# SF32LB56x register map
File version: 1.0
CPU: CM33 r0p1, little endian, MPU, FPU, 3 interrupt priority bits
Registers are 32-bit, read-write, reset 0x0 unless marked. A register's access mark holds for its fields unless they carry their own. Offsets are from the block's base; [hi:lo] are bit positions; {n}, {i} and the like mark numbered series; 'fields as' and 'values as' point back to an identical list.

## HPSYS_CFG
Base 0x4000B000
0x00 BMR — Boot Mode Register
  [0] BOOT_MODE — 0 - normal, 1 - download mode
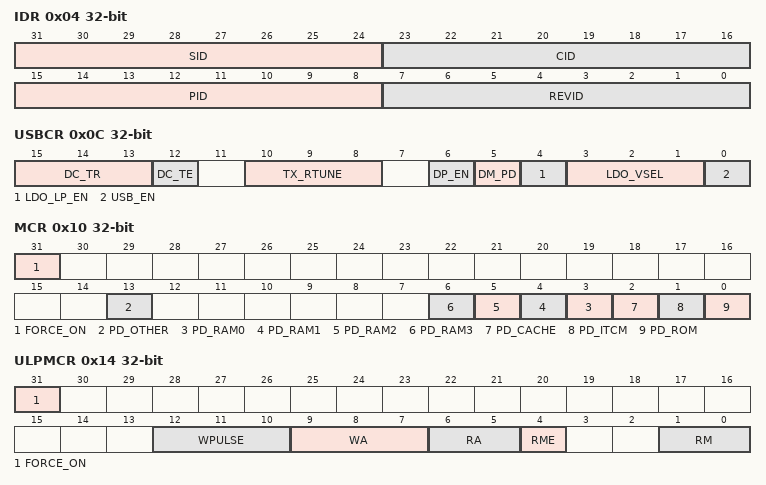
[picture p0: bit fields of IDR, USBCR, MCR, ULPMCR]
0x04 IDR — ID Register
  [31:24] SID — Series ID
  [23:16] CID — Chip ID
  [15:8] PID — Package ID
  [7:0] REVID — Revision ID
0x08 SCR — Security Control Register
  [0] FKEY_MODE — reserved for debug
0x0C USBCR — USB Control register
  [15:13] DC_TR — reserved for debug
  [12] DC_TE — reserved for debug
  [10:8] TX_RTUNE — TX outp impedance tuning 0 = 50 Ohm, 1 = 46 Ohm, 2 = 43 Ohm, 3 = 40 Ohm, 4 = 37.5 Ohm, 5 = 35 Ohm, 6 = 33 Ohm, 7 = 31.5 Ohm
  [6] DP_EN — 0:disable dp pull up or pull down 1:enable dp pull or pull down
  [5] DM_PD — enable DM 15k Ohm pull down resistor
  [4] LDO_LP_EN — 2.5V LDO low power mode enable. 0 = 240 uA, 1 = 50 uA
  [3:1] LDO_VSEL — 2.5V LDO output voltage setting 0 = 2.40 V, 1 = 2.47 V, 2 = 2.53 V, 3 = 2.60 V, 4 = 2.60 V, 5 = 2.67 V, 6 = 2.73 V, 7 = 2.8 V
  [0] USB_EN — USB PHY enable, turn on power swith, power up LDO and bias
0x10 MCR — Memory Control register
  [31] FORCE_ON — reserved for debug
  [13] PD_OTHER — reserved for debug
  [n+3] PD_RAM{n} (n=0..3) — reserved for debug
  [2] PD_CACHE — reserved for debug
  [1] PD_ITCM — reserved for debug
  [0] PD_ROM — reserved for debug
0x14 ULPMCR — ULP Memory Control register
  [31] FORCE_ON — reserved for debug
  [12:10] WPULSE — reserved for debug
  [9:7] WA — reserved for debug
  [6:5] RA — reserved for debug
  [4] RME — reserved for debug
  [1:0] RM — reserved for debug
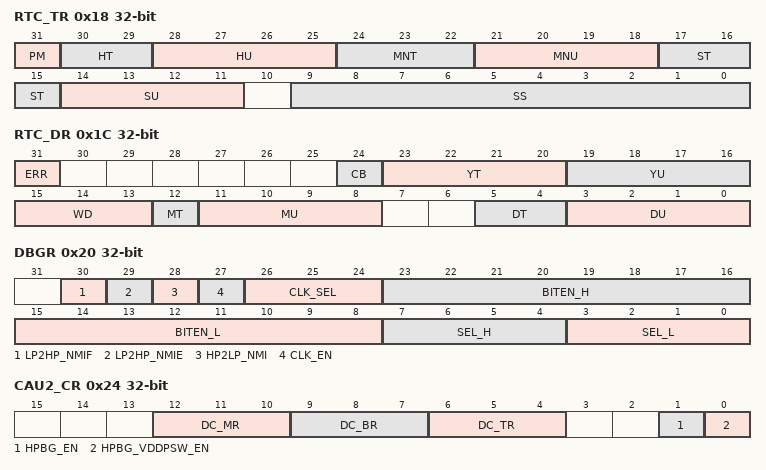
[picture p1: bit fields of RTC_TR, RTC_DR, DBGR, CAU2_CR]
0x18 RTC_TR — Mirrored RTC Time Register
  [31] PM — AM/PM notation 0: AM 1: PM
  [30:29] HT — Hour tens in BCD format
  [28:25] HU — Hour units in BCD format
  [24:22] MNT — Minute tens in BCD format
  [21:18] MNU — Minute units in BCD format
  [17:15] ST — Second tens in BCD format
  [14:11] SU — Second units in BCD format
  [9:0] SS — Sub-second counter
0x1C RTC_DR — Mirrored RTC Date Register
  [31] ERR — reserved for debug
  [24] CB — Century flag
  [23:20] YT — Year tens in BCD format
  [19:16] YU — Year units in BCD format
  [15:13] WD — Week day units 000: forbidden 001: Monday ... 111: Sunday
  [12] MT — Month tens in BCD format
  [11:8] MU — Month units in BCD format
  [5:4] DT — Date tens in BCD format
  [3:0] DU — Date units in BCD format
0x20 DBGR — Debug Select Register
  [30] LP2HP_NMIF — LP2HP NMI interrupt flag
  [29] LP2HP_NMIE — LP2HP NMI interrupt enable
  [28] HP2LP_NMI — set 1 to send NMI interrupt to LCPU
  [27] CLK_EN — reserved for debug
  [26:24] CLK_SEL — reserved for debug
  [23:16] BITEN_H — reserved for debug
  [15:8] BITEN_L — reserved for debug
  [7:4] SEL_H — reserved for debug
  [3:0] SEL_L — reserved for debug
0x24 CAU2_CR — CAU2 Control Register
  [12:10] DC_MR — reserved for debug
  [9:7] DC_BR — reserved for debug
  [6:4] DC_TR — reserved for debug
  [1] HPBG_EN — reserved for debug
  [0] HPBG_VDDPSW_EN — reserved for debug
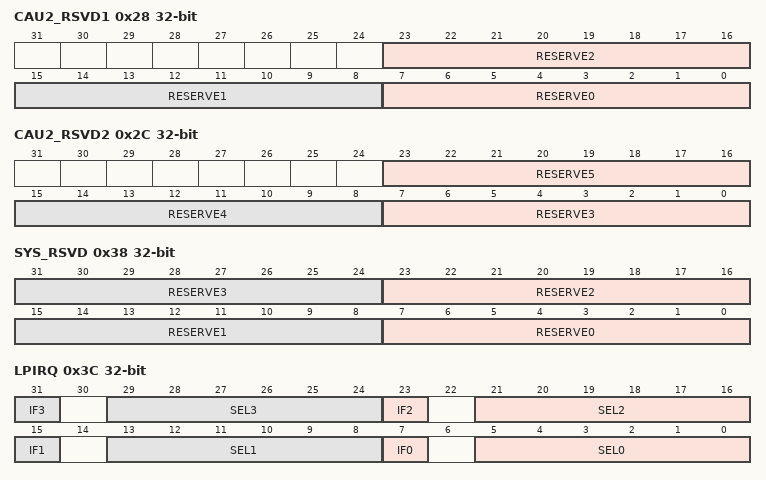
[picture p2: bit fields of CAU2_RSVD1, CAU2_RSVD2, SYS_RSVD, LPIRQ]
0x28 CAU2_RSVD1 — CAU2 RSVD Register1
  [23:16] RESERVE2 — reserved for debug
  [15:8] RESERVE1 — reserved for debug
  [7:0] RESERVE0 — reserved for debug
0x2C CAU2_RSVD2 — CAU2 RSVD Register2
  [23:16] RESERVE5 — reserved for debug
  [15:8] RESERVE4 — reserved for debug
  [7:0] RESERVE3 — reserved for debug
0x38 SYS_RSVD — HPSYS RSVD Register
  [8n+7:8n] RESERVE{n} (n=0..3) — reserved for debug
0x3C LPIRQ — Interrupt Selection for LCPU
  [8n+7] IF{n} (n=0..3) — hp2lp{n} interrupt status. Write 1 to clear.
  [8n+5:8n] SEL{n} (n=0..3) — select hp2lp{n} interrupt source
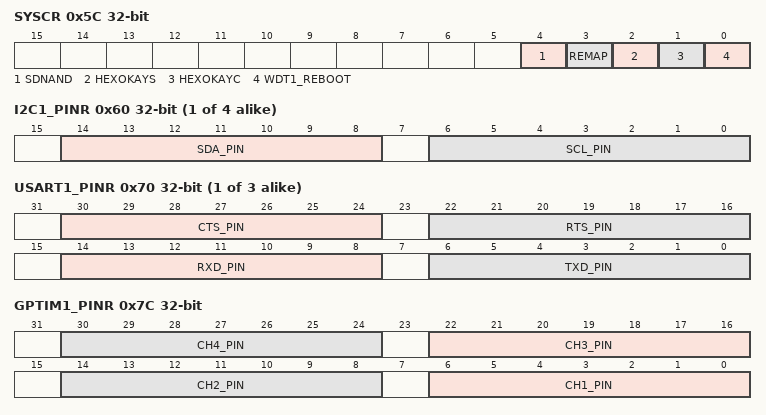
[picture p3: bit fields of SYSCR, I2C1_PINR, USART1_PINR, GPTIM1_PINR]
0x5C SYSCR — System Configure Register
  [4] SDNAND — 0: MPI3 AHB space is allocated to MPI3 1: MPI3 AHB space is allocated to SDMMC2
  [3] REMAP — reserved for debug
  [2] HEXOKAYS — reserved for debug
  [1] HEXOKAYC — reserved for debug
  [0] WDT1_REBOOT — If set to 1, WDT1 reset will reboot the whole chip
{0x5C+4i} I2C{i}_PINR (i=1..4) — I2C{i} Pin Register
  [14:8] SDA_PIN — Connect function pin to selected IO(PA). 0 to 78 for PA00 to PA78. Other values for floating.
  [6:0] SCL_PIN — Connect function pin to selected IO(PA). 0 to 78 for PA00 to PA78. Other values for floating.
{0x6C+4i} USART{i}_PINR (i=1..3) — USART{i} Pin Register
  [30:24] CTS_PIN — Connect function pin to selected IO(PA). 0 to 78 for PA00 to PA78. Other values for floating.
  [22:16] RTS_PIN — Connect function pin to selected IO(PA). 0 to 78 for PA00 to PA78. Other values for floating.
  [14:8] RXD_PIN — Connect function pin to selected IO(PA). 0 to 78 for PA00 to PA78. Other values for floating.
  [6:0] TXD_PIN — Connect function pin to selected IO(PA). 0 to 78 for PA00 to PA78. Other values for floating.
0x7C GPTIM1_PINR — GPTIM1 Pin Register
  [8n-2:8n-8] CH{n}_PIN (n=1..4) — Connect function pin to selected IO(PA). 0 to 78 for PA00 to PA78. Other values for floating.
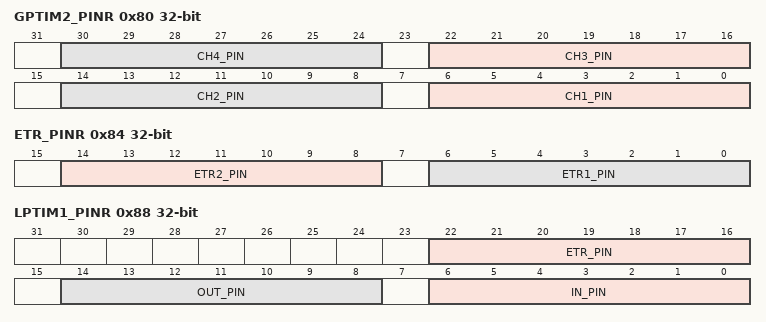
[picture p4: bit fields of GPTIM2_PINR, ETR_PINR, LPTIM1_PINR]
0x80 GPTIM2_PINR — GPTIM2 Pin Register
  fields as GPTIM1_PINR
0x84 ETR_PINR — GPTIM ETR Pin Register
  [14:8] ETR2_PIN — Connect GPTIM2_ETR to selected IO(PA). 0 to 44 for PA00 to PA44. Other values for floating.
  [6:0] ETR1_PIN — Connect GPTIM1_ETR to selected IO(PA). 0 to 44 for PA00 to PA44. Other values for floating.
0x88 LPTIM1_PINR — LPTIM1 Pin Register
  [22:16] ETR_PIN — Connect function pin to selected IO(PA). 0 to 78 for PA00 to PA78. Other values for floating.
  [14:8] OUT_PIN — Connect function pin to selected IO(PA). 0 to 78 for PA00 to PA78. Other values for floating.
  [6:0] IN_PIN — Connect function pin to selected IO(PA). 0 to 78 for PA00 to PA78. Other values for floating.
